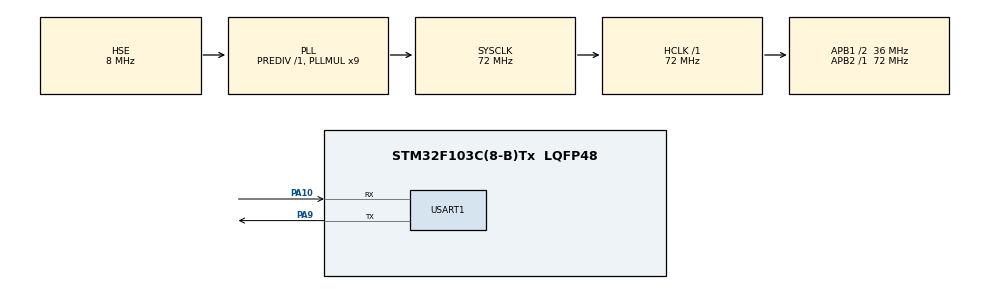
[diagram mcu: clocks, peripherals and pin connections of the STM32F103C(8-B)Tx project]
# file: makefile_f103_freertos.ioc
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Mcu.Family=STM32F1
Mcu.Name=STM32F103C(8-B)Tx
Mcu.Package=LQFP48
NVIC.PriorityGroup=NVIC_PRIORITYGROUP_4
PA10.Mode=Asynchronous
PA10.Signal=USART1_RX
PA13.Mode=Serial_Wire
PA13.Signal=SYS_JTMS-SWDIO
PA14.Mode=Serial_Wire
PA14.Signal=SYS_JTCK-SWCLK
PA9.Mode=Asynchronous
PA9.Signal=USART1_TX
PD0-OSC_IN.Mode=HSE-External-Oscillator
PD0-OSC_IN.Signal=RCC_OSC_IN
PD1-OSC_OUT.Mode=HSE-External-Oscillator
PD1-OSC_OUT.Signal=RCC_OSC_OUT
ProjectManager.HeapSize=0x400
ProjectManager.StackSize=0x800
ProjectManager.TargetToolchain=Makefile
RCC.AHBFreq_Value=72000000
RCC.APB1CLKDivider=RCC_HCLK_DIV2
RCC.APB1Freq_Value=36000000
RCC.APB1TimFreq_Value=72000000
RCC.APB2Freq_Value=72000000
RCC.APB2TimFreq_Value=72000000
RCC.HCLKFreq_Value=72000000
RCC.PLLMUL=RCC_PLL_MUL9
RCC.PLLSourceVirtual=RCC_PLLSOURCE_HSE
RCC.SYSCLKFreq_VALUE=72000000
RCC.SYSCLKSource=RCC_SYSCLKSOURCE_PLLCLK
RCC.USBFreq_Value=72000000
USART1.VirtualMode=VM_ASYNC
board=custom

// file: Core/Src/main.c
/* USER CODE BEGIN Header */
/**
 ******************************************************************************
 * @file           : main.c
 * @brief          : Main program body
 ******************************************************************************
 * @attention
 *
 * <h2><center>&copy; Copyright (c) 2022 STMicroelectronics.
 * All rights reserved.</center></h2>
 *
 * This software component is licensed by ST under BSD 3-Clause license,
 * the "License"; You may not use this file except in compliance with the
 * License. You may obtain a copy of the License at:
 *                        opensource.org/licenses/BSD-3-Clause
 *
 ******************************************************************************
 */
/* USER CODE END Header */
#include "main.h"
#include "usart.h"
#include "gpio.h"

/* USER CODE BEGIN Includes */
#include "FreeRTOSConfig.h"
#include "FreeRTOS.h"
#include "task.h"

extern UART_HandleTypeDef huart1;

#include "stdio.h"
int _write(int fd, char *pBuffer, int size)
{
  for (int i = 0; i < size; i++)
  {
    while ((USART1->SR & 0X40) == 0)
      ;                               //等待上一次串口数据发送完�???
    USART1->DR = (uint8_t)pBuffer[i]; //写DR,串口1将发送数�???
  }
  return size;
}

/* USER CODE END Includes */

/* USER CODE BEGIN PV */
TaskHandle_t StartTask_Handler;
TaskHandle_t task1;
TaskHandle_t task2;
/* USER CODE END PV */

void SystemClock_Config(void);
/* USER CODE BEGIN PFP */
void start_task(void *arg);
void task1_led(void *arg);
void task2_serialport(void *arg);
/* USER CODE END PFP */

int main(void)
{

  /* MCU Configuration--------------------------------------------------------*/

  /* Reset of all peripherals, Initializes the Flash interface and the Systick. */
  HAL_Init();

  /* Configure the system clock */
  SystemClock_Config();

  /* Initialize all configured peripherals */
  MX_GPIO_Init();
  MX_USART1_UART_Init();
  /* USER CODE BEGIN 2 */

  xTaskCreate(start_task,          /* 任务入口 */
              "start_task",        /* 任务名称，字符串形式 */
              128,                 /* 任务栈大小，单位为字 */
              NULL,                /* 任务形参 */
              1,                   /* 任务优先�??? ,越大越优�???*/
              &StartTask_Handler); /* 任务句柄 */

  vTaskStartScheduler();

  /* USER CODE END 2 */

  /* Infinite loop */
  /* USER CODE BEGIN WHILE */
  while (1)
  {
    vTaskDelay(100);
    printf("hello world\r\n");
    // HAL_UART_Transmit(&huart1, "hello world\r\n", sizeof("hello world\r\n"), 1000);
    // HAL_Delay(100 - 1);
    /* USER CODE END WHILE */

  }
}

void SystemClock_Config(void)
{
  RCC_OscInitTypeDef RCC_OscInitStruct = {0};
  RCC_ClkInitTypeDef RCC_ClkInitStruct = {0};

  /** Initializes the RCC Oscillators according to the specified parameters
   * in the RCC_OscInitTypeDef structure.
   */
  RCC_OscInitStruct.OscillatorType = RCC_OSCILLATORTYPE_HSE;
  RCC_OscInitStruct.HSEState = RCC_HSE_ON;
  RCC_OscInitStruct.HSEPredivValue = RCC_HSE_PREDIV_DIV1;
  RCC_OscInitStruct.HSIState = RCC_HSI_ON;
  RCC_OscInitStruct.PLL.PLLState = RCC_PLL_ON;
  RCC_OscInitStruct.PLL.PLLSource = RCC_PLLSOURCE_HSE;
  RCC_OscInitStruct.PLL.PLLMUL = RCC_PLL_MUL9;
  if (HAL_RCC_OscConfig(&RCC_OscInitStruct) != HAL_OK)
  {
    Error_Handler();
  }

  /** Initializes the CPU, AHB and APB buses clocks
   */
  RCC_ClkInitStruct.ClockType = RCC_CLOCKTYPE_HCLK | RCC_CLOCKTYPE_SYSCLK | RCC_CLOCKTYPE_PCLK1 | RCC_CLOCKTYPE_PCLK2;
  RCC_ClkInitStruct.SYSCLKSource = RCC_SYSCLKSOURCE_PLLCLK;
  RCC_ClkInitStruct.AHBCLKDivider = RCC_SYSCLK_DIV1;
  RCC_ClkInitStruct.APB1CLKDivider = RCC_HCLK_DIV2;
  RCC_ClkInitStruct.APB2CLKDivider = RCC_HCLK_DIV1;

  if (HAL_RCC_ClockConfig(&RCC_ClkInitStruct, FLASH_LATENCY_2) != HAL_OK)
  {
    Error_Handler();
  }
}

/* USER CODE BEGIN 4 */
void start_task(void *arg)
{
  taskENTER_CRITICAL();    //进入临界�???
  xTaskCreate(task1_led,   /* 任务入口 */
              "task1_led", /* 任务名称，字符串形式 */
              128,         /* 任务栈大小，单位为字 */
              NULL,        /* 任务形参 */
              2,           /* 任务优先�??? ,越大越优�???*/
              task1);      /* 任务句柄 */

  xTaskCreate(task2_serialport,   /* 任务入口 */
              "task2_serialport", /* 任务名称，字符串形式 */
              128,                /* 任务栈大小，单位为字 */
              NULL,               /* 任务形参 */
              3,                  /* 任务优先�??? ,越大越优�???*/
              task2);             /* 任务句柄 */

  taskEXIT_CRITICAL();            //�???出临界区
  vTaskDelete(StartTask_Handler); //删除�???始任�???
}
void task1_led(void *arg)
{
  taskENTER_CRITICAL(); //进入临界�???
  GPIO_InitTypeDef GPIO_InitStruct = {0};
  __HAL_RCC_GPIOB_CLK_ENABLE();
  GPIO_InitStruct.Pin = GPIO_PIN_12;
  GPIO_InitStruct.Mode = GPIO_MODE_OUTPUT_PP;
  GPIO_InitStruct.Pull = GPIO_NOPULL;
  GPIO_InitStruct.Speed = GPIO_SPEED_HIGH;
  HAL_GPIO_Init(GPIOB, &GPIO_InitStruct);
  HAL_GPIO_WritePin(GPIOB, GPIO_PIN_12, (GPIO_PinState)0);
  taskEXIT_CRITICAL(); //�???出临界区
  while (1)
  {
    HAL_GPIO_TogglePin(GPIOB, GPIO_PIN_12);
    vTaskDelay(100);
  }
}

void task2_serialport(void *arg)
{
  while (1)
  {

    printf("hello world\r\n");
    vTaskDelay(100);
  }
}

/* USER CODE END 4 */

void Error_Handler(void)
{
  __disable_irq();
  while (1)
  {
  }
}
